# MSS_DMA_REG register map
Vendor: Texas Instruments
Peripheral module from a debugger description file (folder radar).
Registers are 32-bit, read-write, no defined reset value unless marked. A register's access mark holds for its fields unless they carry their own. Offsets are as the file gives them; lines under a group give offsets from that group; [hi:lo] are bit positions; {n}, {i} and the like mark numbered series; 'fields as' and 'values as' point back to an identical list; <NAME> marks a mode.

## MSS_DMA_REG
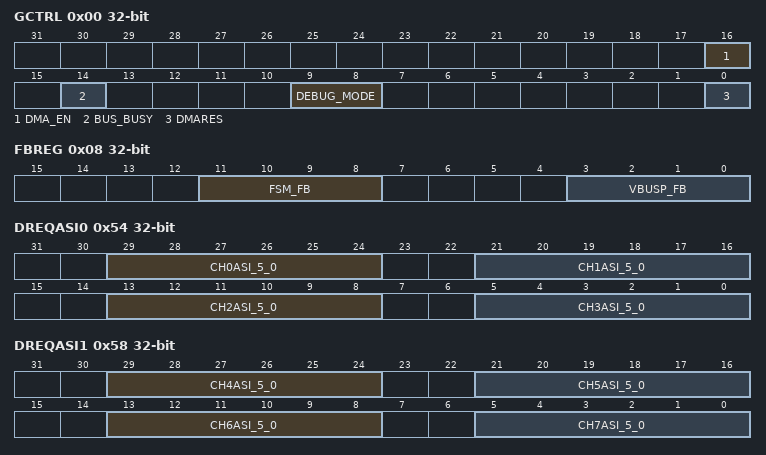
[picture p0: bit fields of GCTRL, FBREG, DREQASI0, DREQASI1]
0x00 GCTRL access per field — Sets Power-down mode, debug mode...
  [16] DMA_EN rw — DMA Enable bit
  [14] BUS_BUSY ro — BUS BUSY This bit indicates status of DMA external AHB bus status. 0 DMA’s external bus is not busy in data transfers. 1 DMA’s external bus is busy in data transfers
  [9:8] DEBUG_MODE rw — DEBUG MODE 11 immediate stop at an DMA arbitration boundary and continue after suspend 10 finish current frame transfer 01 finish current block transfer 00 ignore suspend
  [0] DMARES rw — DMA Software Reset Writing a 1 to this bit resets the DMA state machine and all control registers. Control packets are not reset when DMA software reset is active. Writing a zero disable SW reset.
0x04 PEND — Channel pending register
  [31:0] PEND — Channel Pending Register Writing has no effect. Reading from PEND gives the channel pending information no matter if the channel was initiated by SW or HW. Once set, it remains set even if the corresponding channel is disabled via HWCHENA or SWCHENA. The pending bit is automatically cleared for the following conditions: 1)At the end of a frame or a block transfer depending on how the channel is triggered as programmed in the TTYPE bit field of Section 1.6.3.4, "CHANNEL CONTROL Register (CHCTRL)" . 2)The control packet is modified after the pending bit is set. 3)An AHB bus error occurs. 1 the associated channel is pending and is waiting for service. 0 the associated channel is inactive.
0x08 FBREG access per field — Fall back register for EMC
  [11:8] FSM_FB rw — FSM_FB: FSM Fallback feature Used to switch off RTL clock gating for all FSM logics used for saving power. “1010” = Disable RTL clock gating in RTL. “0101” = Enable RTL clock gating in RTL. others = no effect will be in same state as before
  [3:0] VBUSP_FB rw — VBUSP_FB: VBUSP Fallback feature Used to switch off RTL clock gating for all VBUSP logics used for saving power. “1010” = Disable RTL clock gating in RTL. “0101” = Enable RTL clock gating in RTL. others = no effect will be in same state as before
0x0C DMASTAT — Channel active information
  [31:0] STCH — 0STCH: Status of DMA channels 1 channel active (means channel is currently in DMA’s execution queue). 0 channel inactive. Since the DMA has two Ports only two channels can be active at a time. Writing has no effect. Note: The status of a channel currently in DMA’s execution queue remains active even if emulation mode is entered or DMA is disabled via DMA_EN bit
{0x8+8i} MSS_DMA_Reserved{i} access not given (i=1..9)
0x14 HWCHENAS — Enables a channel for HW trigger
  [31:0] HWCHENA — HWCHENA: HW Channel Enable Bit Writing a one to a bit enables the according channel for HW triggering. Writing a zero has no effect. An active HW DMA request can not initiate DMA transfer unless the associated HW enable bit is set. The associated HW enable bit is cleared automatically for the following conditions: 1)At the end of a block transfer if autoinitiation bit AIM in Section 1.6.3.4, "CHANNEL CONTROL Register (CHCTRL)" is not active. 2)If an AHB bus error is detected for an active channel as indicated by HRESP signal. Reading from HWCHENAS gives the status (enabled/disabled) of channels 0 through 31. 1 the associated channel is enabled for HW triggering. 0 the associated channel is disabled for HW triggering.
0x1C HWCHENAR — Disables a channel for HW trigger
  [31:0] HWCHDIS — HW Channel Disable Bit. Writing a one to a bit disables the according channel for HW triggering. Writing a zero has no effect. Reading from CHENAR gives the status (enabled/disabled) of channels 0 through 31. 1 the associated channel is enabled for HW triggering. 0 the associated channel is disabled for HW triggering. Note: All Set and Reset registers throughout DMA controller such as HWCHENAS and HWCHENAR are two logical locations mapped to one physical register.
0x24 SWCHENAS — Activate a SW request
  [31:0] SWCHENA — SWCHENA: SW Channel Enable Bit. Writing a one to a bit trigger a SW request on the associated channel to start DMA transaction. The associated bit is automatically cleared by the following conditions. 1)The associated bit is cleared after one frame transfer if the TTYPE bit in Section 1.6.3.4, "CHANNEL CONTROL Register (CHCTRL)" is programmed for frame transfer. 2)The associated bit is cleared after one block transfer if the corresponding TTYPE bit is programmed for block transfer and the autoinitiation bit is not enabled. 3)The control packet is modified after the pending bit is set. 4)The associated bit is cleared after one block transfer when TTYPE bit is programmed for blocks transfer and if the corresponding bit in HW Channel Enable Register (HWCHENAS) is enabled. When a channel is enabled for both HW and SW, the state machine will initiate transfers based on the SW first. After one block transfer is complete, the associated bit in the SWCHENA register is then cleared. The same channel is serviced again by a HW DMA request. 5)The associated bit is cleared if an AHB bus error is detected for an active channel as indicated by HRESP signal. Reading from SWCHENAS gives the status (enabled/disabled) of channels 0 through 31 1 the associated channel was triggered by SW request. 0 the associated channel was not triggered by SW request
0x2C SWCHENAR — Disables a SW request
  [31:0] SWCHDIS — SWCHDIS: SW Channel Disable Bit Writing a one to a bit disables the according channel from SW trigger. Writing a zero has no effect. Reading from SWCHENAR gives the status (enabled/disabled) of channels 0 through 31. 1 the associated channel was triggered by SW. 0 the associated channel was not triggered by SW.
0x34 CHPRIOS — Enables a channel
  [31:0] CPH — CPH: Channel Priority Set Bit. Writing a one to a bit assigns the according channel to the high priority queue. Writing a zero has no effect. Reading from CHPRIOS gives the status (high priority 1 / low priority 0) of channels 0 through 31. 1 the associated channel is assigned to high priority queue. 0 the associated channel is assigned to low priority queue.
0x3C CHPRIOR — Disables a channel
  [31:0] CPL — CPL: Channel Priority Reset Bit Writing a one to a bit assigns the according channel to the low priority queue. Writing a zero has no effect. Reading from CHPRIOR gives the status (high priority 1 / low priority 0) of channels 0 through 31. 1 the associated channel is assigned to high priority queue. 0 the associated channel is assigned to low priority queue.
0x44 GCHIENAS — Enables the specific channel interrupts
  [31:0] GCHIE — GCHIE: Global Channel Interrupt Enable Bit. Writing a one to a bit enables the according channel interrupt. Writing a zero has no effect. Reading from GCHIENAS gives the status (enabled/disabled) of channels 0 through 31. 1 the associated channel is enabled for interrupt. 0 the associated channel is disabled for interrupt.
0x4C GCHIENAR — Disables the specific channel interrupts
  [31:0] GCHID — GCHID: Global Channel Interrupt Disable Bit Writing a one to a bit disables the according channel interrupt. Writing a zero has no effect. Reading from GCHIENAR gives the status (enabled/disabled) of channels 0 through 31. 1 the associated channel is enabled for interrupt. 0 the associated channel is disabled for interrupt
0x54 DREQASI0 access per field — DMA channel to request line assignment
  [29:24] CH0ASI_5_0 rw — CH0ASI: Channel 0 Assignment Bits This bit field chooses the DMA request assignment for channel 0. Writing 0 means DMA request line 0 coming in to the DMA will trigger channel 0. Writing 3F means DMA request line 63 will trigger channel 0.
  [21:16] CH1ASI_5_0 rw — CH1ASI: Channel 1 Assignment Bits This bit field chooses the DMA request assignment for channel 1.
  [13:8] CH2ASI_5_0 rw — CH2ASI: Channel 2 Assignment Bits This bit field chooses the DMA request assignment for channel 2.
  [5:0] CH3ASI_5_0 rw — CH3ASI: Channel 3 Assignment Bits. This bit field chooses the DMA request assignment for channel 3
0x58 DREQASI1 access per field — DMA channel to request line assignment
  [29:24] CH4ASI_5_0 rw — CH4ASI: Channel 4 Assignment Bits This bit field chooses the DMA request assignment for channel 4. .
  [21:16] CH5ASI_5_0 rw — CH5ASI: Channel 5 Assignment Bits This bit field chooses the DMA request assignment for channel 5
  [13:8] CH6ASI_5_0 rw — CH6ASI: Channel 6 Assignment Bits This bit field chooses the DMA request assignment for channel 6
  [5:0] CH7ASI_5_0 rw — CH7ASI: Channel 7 Assignment Bits. This bit field chooses the DMA request assignment for channel 7
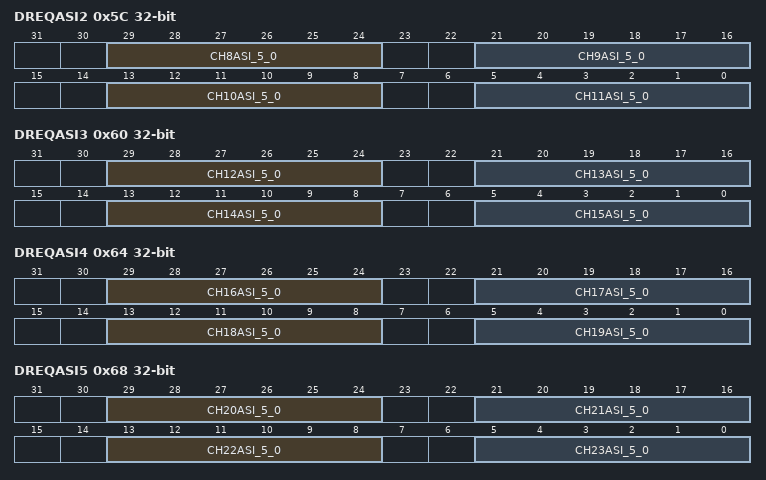
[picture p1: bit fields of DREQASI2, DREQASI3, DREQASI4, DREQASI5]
0x5C DREQASI2 access per field — DMA channel to request line assignment
  [29:24] CH8ASI_5_0 rw — CH8ASI: Channel 8 Assignment Bits This bit field chooses the DMA request assignment for channel 8
  [21:16] CH9ASI_5_0 rw — CH9ASI: Channel 9 Assignment Bits This bit field chooses the DMA request assignment for channel 9
  [13:8] CH10ASI_5_0 rw — CH10ASI: Channel 10 Assignment Bits This bit field chooses the DMA request assignment for channel 10
  [5:0] CH11ASI_5_0 rw — CH11ASI: Channel 11 Assignment Bits. This bit field chooses the DMA request assignment for channel 11
0x60 DREQASI3 access per field — DMA channel to request line assignment
  [29:24] CH12ASI_5_0 rw — CH12ASI: Channel 12 Assignment Bits This bit field chooses the DMA request assignment for channel 12
  [21:16] CH13ASI_5_0 rw — CH13ASI: Channel 13 Assignment Bits This bit field chooses the DMA request assignment for channel 13
  [13:8] CH14ASI_5_0 rw — CH14ASI: Channel 14 Assignment Bits This bit field chooses the DMA request assignment for channel 14
  [5:0] CH15ASI_5_0 rw — CH15ASI: Channel 15 Assignment Bits. This bit field chooses the DMA request assignment for channel 15
0x64 DREQASI4 access per field — DMA channel to request line assignment
  [29:24] CH16ASI_5_0 rw — CH16ASI: Channel 16 Assignment Bits This bit field chooses the DMA request assignment for channel 16
  [21:16] CH17ASI_5_0 rw — CH17ASI: Channel 17 Assignment Bits This bit field chooses the DMA request assignment for channel 17
  [13:8] CH18ASI_5_0 rw — CH18ASI: Channel 18 Assignment Bits This bit field chooses the DMA request assignment for channel 18
  [5:0] CH19ASI_5_0 rw — CH18ASI: Channel 19 Assignment Bits. This bit field chooses the DMA request assignment for channel 19
0x68 DREQASI5 access per field — DMA channel to request line assignment
  [29:24] CH20ASI_5_0 rw — CH20ASI: Channel 20 Assignment Bits This bit field chooses the DMA request assignment for channel 20
  [21:16] CH21ASI_5_0 rw — CH21ASI: Channel 21 Assignment Bits This bit field chooses the DMA request assignment for channel 21
  [13:8] CH22ASI_5_0 rw — CH22ASI: Channel 22 Assignment Bits This bit field chooses the DMA request assignment for channel 22
  [5:0] CH23ASI_5_0 rw — CH23ASI: Channel 23 Assignment Bits. This bit field chooses the DMA request assignment for channel 23
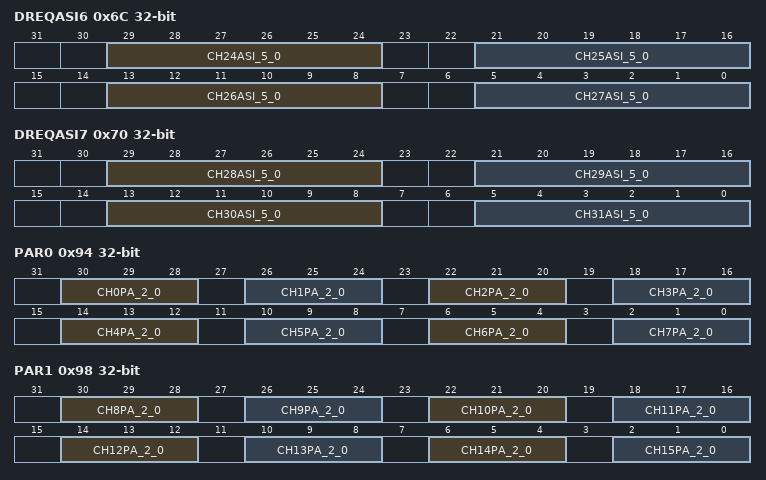
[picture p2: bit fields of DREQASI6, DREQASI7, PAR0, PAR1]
0x6C DREQASI6 access per field — DMA channel to request line assignment
  [29:24] CH24ASI_5_0 rw — CH24ASI: Channel 24 Assignment Bits This bit field chooses the DMA request assignment for channel 24
  [21:16] CH25ASI_5_0 rw — CH25SI: Channel 25 Assignment Bits This bit field chooses the DMA request assignment for channel 25
  [13:8] CH26ASI_5_0 rw — CH26ASI: Channel 26 Assignment Bits This bit field chooses the DMA request assignment for channel 26
  [5:0] CH27ASI_5_0 rw — CH27ASI: Channel 27 Assignment Bits. This bit field chooses the DMA request assignment for channel 27
0x70 DREQASI7 access per field — DMA channel to request line assignment
  [29:24] CH28ASI_5_0 rw — CH28ASI: Channel 28 Assignment Bits This bit field chooses the DMA request assignment for channel 28
  [21:16] CH29ASI_5_0 rw — CH29SI: Channel 29 Assignment Bits This bit field chooses the DMA request assignment for channel 29
  [13:8] CH30ASI_5_0 rw — CH30ASI: Channel 30 Assignment Bits This bit field chooses the DMA request assignment for channel 30
  [5:0] CH31ASI_5_0 rw — CH31ASI: Channel 31 Assignment Bits. This bit field chooses the DMA request assignment for channel 31
{0x4C+4i} MSS_DMA_Reserved{i} access not given (i=10..17)
0x94 PAR0 access per field — DMA channel to port assignment
  [30:28] CH0PA_2_0 rw — CH0PA These bit fields determine which port channel 0 is assigned. 1xx Port B 011 Port A2 only 010 Port A1 only 001 Port A1/2 combined, A2 read / A1 write 000 Port A1/2 combined, A1 read / A2 write
  [30-4n:28-4n] CH{n}PA_2_0 rw (n=1..7) — CH{n}PA These bit fields determine which port channel {n} is assigned
0x98 PAR1 access per field — DMA channel to port assignment
  [30:28] CH8PA_2_0 rw — CH8PA These bit fields determine which port channel 8 is assigned. 1xx Port B 011 Port A2 only 010 Port A1 only 001 Port A1/2 combined, A2 read / A1 write 000 Port A1/2 combined, A1 read / A2 write
  [62-4n:60-4n] CH{n}PA_2_0 rw (n=9..15) — CH{n}PA These bit fields determine which port channel {n} is assigned
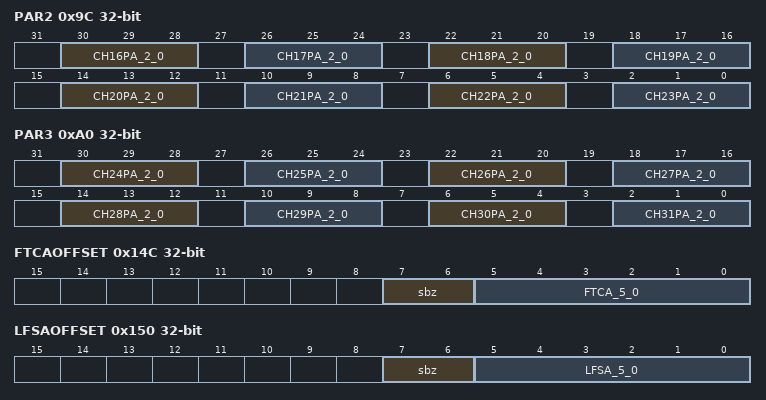
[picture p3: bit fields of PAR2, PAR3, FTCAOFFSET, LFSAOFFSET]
0x9C PAR2 access per field — DMA channel to port assignment
  [30:28] CH16PA_2_0 rw — CH16PA These bit fields determine which port channel 16 is assigned. 1xx Port B 011 Port A2 only 010 Port A1 only 001 Port A1/2 combined, A2 read / A1 write 000 Port A1/2 combined, A1 read / A2 write
  [94-4n:92-4n] CH{n}PA_2_0 rw (n=17..23) — CH{n}PA These bit fields determine which port channel {n} is assigned
0xA0 PAR3 access per field — DMA channel to port assignment
  [30:28] CH24PA_2_0 rw — CH24PA These bit fields determine which port channel 24 is assigned. 1xx Port B 011 Port A2 only 010 Port A1 only 001 Port A1/2 combined, A2 read / A1 write 000 Port A1/2 combined, A1 read / A2 write
  [126-4n:124-4n] CH{n}PA_2_0 rw (n=25..28) — CH{n}PA These bit fields determine which port channel {n} is assigned
  [10:8] CH29PA_2_0 rw — CH29PA These bit fields determine which port channel 28 is assigned
  [6:4] CH30PA_2_0 rw — CH30PA These bit fields determine which port channel 30 is assigned
  [2:0] CH31PA_2_0 rw — CH31PA These bit fields determine which port channel 31 is assigned
{0x5C+4i} MSS_DMA_Reserved{i} access not given (i=18..21)
0xB4 FTCMAP — Assignment of interrupt lines to either ARM CPU or DSP CPU
  [31:0] FTCAB — FTCAB: Frame Transfer Complete Interrupt to Group A or Group B 1 routes FTC interrupt of the corresponding channel to Group B. 0 routes FTC interrupt of the corresponding channel to Group A. Note: Group A interrupts (FTC, LFS, HBC, BTC and BER) are routed to ARM CPU. Group B interrupts (FTC, LFS, HBC, BTC and BER) are routed to DSP CPU.
{0x8+8i} MSS_DMA_Reserved{i} access not given (i=22..31)
0xBC LFSMAP — Assignment of interrupt lines to either ARM CPU or DSP CPU
  [31:0] LFSAB — LFSAB: Last Frame Started Interrupt to Group A or Group B 1 routes LFS interrupt of the corresponding channel to Group B. 0 routes LFS interrupt of the corresponding channel to Group A.
0xC4 HBCMAP — Assignment of interrupt lines to either ARM CPU or DSP CPU
  [31:0] HBCAB — HBCAB: Half Block Complete Interrupt to Group A or Group B 1 routes HBC interrupt of the corresponding channel to Group B. 0 routes HBC interrupt of the corresponding channel to Group A.
0xCC BTCMAP — Assignment of interrupt lines to either ARM CPU or DSP CPU
  [31:0] BTCAB — BTCAB: Block Transfer Complete Interrupt to Group A or Group B 1 routes BTC interrupt of the corresponding channel to Group B. 0 routes BTC interrupt of the corresponding channel to Group A.
0xD4 BERMAP — Assignment of interrupt lines to either ARM CPU or DSP CPU
  [31:0] BERAB — BERAB: Bus Error Interrupt to Group A or Group B. 1 routes BER interrupt of the corresponding channel to Group B. 0 routes BER interrupt of the corresponding channel to Group A.
0xDC FTCINTENAS — Enables a FTC interrupt for channels 0-31
  [31:0] FTCINTENA — FTCINTENA: FTC (Frame Transfer Complete) Interrupt Enable Bit. Writing a one to a bit enables the interrupt of the according channel. Writing a zero has no effect. Reading from FTCINTENAS gives the status (interrupt enabled/disabled) of channels 0 through 31. 1 the associated FTC interrupt of a channel is enabled. 0 the associated FTC interrupt of a channel is disabled.
0xE4 FTCINTENAR — Disables a FTC interrupt for channels 0-31
  [31:0] FTCINTDIS — FTCINTDIS: FTC (Frame Transfer Complete) Interrupt Disable Bit. Writing a one to a bit disables the interrupt of the according channel. Writing a zero has no effect. Reading from FTCINTENAR gives the status (interrupt enabled/disabled) of channels 0 through 31. 1 the associated FTC interrupt of a channel is enabled. 0 the associated FTC interrupt of a channel is disabled.
0xEC LFSINTENAS — Enables a LFS interrupt for channels 0-31
  [31:0] LFSINTENA — LFSINTENA: LFS (last Frame Started) Interrupt Enable Bit. Writing a one to a bit enables the interrupt of the according channel. Writing a zero has no effect Reading from LFSINTENAS gives the status (interrupt enabled/disabled) of channels 0 through 31. 1 the associated LFS interrupt of a channel is enabled. 0 the associated LFS interrupt of a channel is disabled
0xF4 LFSINTENAR — Disables a LFS interrupt for channels 0-31
  [31:0] LFSINTDIS — LFSINTDIS: LFS (Last Frame Started) Interrupt Disable Bit. Writing a one to a bit disables the interrupt of the according channel. Writing a zero has no effect. Reading from LFSINTENAR gives the status (interrupt enabled/disabled) of channels 0 through 31. 1 the associated LFS interrupt of a channel is enabled. 0 the associated LFS interrupt of a channel is disabled
0xFC HBCINTENAS — Enables a HBC interrupt for channels 0-31
  [31:0] HBCINTENA — HBCINTENA: HBC (Half Block Complete) Interrupt Enable Bit. Writing a one to a bit enables the interrupt of the according channel. Writing a zero has no effect. Reading from HBCINTENAS gives the status (interrupt enabled/disabled) of channels 0 through 31. 1 the associated HBC interrupt of a channel is enabled. 0 the associated HBC interrupt of a channel is disabled
0x104 HBCINTENAR — Disables a HBC interrupt for channels 0-31
  [31:0] HBCINTDIS — HBCINTDIS: HBC (Half Block Complete) Interrupt Disable Bit. Writing a one to a bit disables the interrupt of the according channel. Writing a zero has no effect Reading from HBCINTENAR gives the status (interrupt enabled/disabled) of channels 0 through 31. 1 the associated HBC interrupt of a channel is enabled. 0 the associated HBC interrupt of a channel is disabled
0x10C BTCINTENAS — Enables a BTC interrupt for channels 0-31
  [31:0] BTCINTENA — BTCINTENA: BTC (Block Transfer Complete) Interrupt Enable Bit. Writing a one to a bit enables the interrupt of the according channel. Writing a zero has no effect. Reading from BTCINTENAS gives the status (interrupt enabled/disabled) of channels 0 through 31. 1 the associated BTC interrupt of a channel is enabled. 0 the associated BTC interrupt of a channel is disabled.
{0x8+8i} MSS_DMA_Reserved{i} access not given (i=33..40)
0x114 BTCINTENAR — Disables a BTC interrupt for channels 0-31
  [31:0] BTCINTDIS — BTCINTDIS: BTC (Block Transfer Complete) Interrupt Disable Bit. Writing a one to a bit disables the interrupt of the according channel. Writing a zero has no effect. Reading from BTCINTENAR gives the status (interrupt enabled/disabled) of channels 0 through 31. 1 the associated BTC interrupt of a channel is enabled. 0 the associated BTC interrupt of a channel is disabled
0x11C GINTFLAG — Each flag bit is an OR of five different interrupt types of the same channel
  [31:0] GINT — GINT: Global Interrupt Flags. Global interrupt flag bit is a OR function of FTC, LFS, HBC, BTC and BER interrupt flags. When a bit is active, it indicates that one or more of the five interrupt types is pending of the corresponding channel
0x124 FTCFLAG — FTC Interrupt flags Channels 0-31
  [31:0] FTC — FTCI: Frame Transfer Complete Flags. If the bit is set a FTC Interrupt of the corresponding channels pending. Writing a 1 clears the according flag. Writing a zero has no effect. Reading from the respected Interrupt Channel Offset register also clears the corresponding flag. 1 the associated FTC interrupt of a channel is pending. 0 the associated FTC interrupt of a channel is not pending. The state of the flag bit can be polled even if the corresponding interrupt enable bit is cleared
0x12C LFSFLAG — LFS Interrupt flags Channels 0-31
  [31:0] LFSI — LFSI: Last Frame Transfer Started Flags If the bit is set a LFS Interrupt of the corresponding channels pending. Writing a 1 clears the according flag. Writing a zero has no effect. Reading from the respected Interrupt Channel Offset register also clears the corresponding flag. 1 the associated LFS interrupt of a channel is pending. 0 the associated LFS interrupt of a channel is not pending. The state of the flag bit can be polled even if the corresponding interrupt enable bit is cleared
0x134 HBCFLAG — HBC Interrupt flags Channels 0-31
  [31:0] HBCI — HBCI: Half of Block Transfer Complete Flags. If the bit is set a HBC Interrupt of the corresponding channels pending. Writing a 1 clears the according flag. Writing a zero has no effect. Reading from the respected Interrupt Channel Offset register also clears the corresponding flag. 1 the associated HBC interrupt of a channel is pending. 0 the associated HBC interrupt of a channel is not pending. The state of the flag bit can be polled even if the corresponding interrupt enable bit is cleared
0x13C BTCFLAG — BTC Interrupt flags Channels 0-31
  [31:0] BTCI — BTCI: Block Transfer Complete Flags. If the bit is set a BTC Interrupt of the corresponding channels pending. Writing a 1 clears the according flag. Writing a zero has no effect. Reading from the respected Interrupt Channel Offset register also clears the corresponding flag. 1 the associated BTC interrupt of a channel is pending. 0 the associated BTC interrupt of a channel is not pending. The state of the flag bit can be polled even if the corresponding interrupt enable bit is cleared
0x144 BERFLAG — BER Interrupt flags Channels 0-31
  [31:0] BERI — BERI: Bus Error Flags. If the bit is set a BER Interrupt of the corresponding channels pending. Writing a 1 clears the according flag. Writing a zero has no effect. Reading from the respected Interrupt Channel Offset register also clears the corresponding flag. 1 the associated BER interrupt of a channel is pending. 0 the associated BER interrupt of a channel is not pending. The state of the flag bit can be polled even if the corresponding interrupt enable bit is cleared.
0x14C FTCAOFFSET ro — Channel causing FTC Interrupt on Group A
  [7:6] sbz — sbz. These bits should be programmed as zero
  [5:0] FTCA_5_0 — FTCA: Channel causing FTC (Frame Transfer Complete) Interrupt Group A. Contains the channel number of the pending interrupt for group A if the corresponding interrupt enable is set. Reading this location clears the corresponding Interrupt pending flag with the highest priority. Please refer to Table 1–10. If FTCA is zero it means no interrupt is pending. FTCA = 1, means channel 0 is pending. FTCA = 2, means channel 1 is pending and so on... FTCA Interrupt Offset Index Interrupt Condition Offset Value Phantom 0x0 Channel 0 FTCA 0x1 Channel 1 FTCA 0x2 | | | | Channel 31 FTCA 0x20
0x150 LFSAOFFSET ro — Channel causing LFS Interrupt on Group A
  [7:6] sbz — 6sbz. These bits should be programmed as zero.
  [5:0] LFSA_5_0 — LFSA: Channel causing LFS (Last Frame Started) Interrupt Group A. Contains the channel number of the pending interrupt for group A if the corresponding interrupt enable is set. Reading this location clears the corresponding Interrupt pending flag with the highest priority. Please refer below table FTCA Interrupt Offset Index Interrupt Condition Offset Value Phantom 0x0 Channel 0 FTCA 0x1 Channel 1 FTCA 0x2 | | | | Channel 31 FTCA 0x20
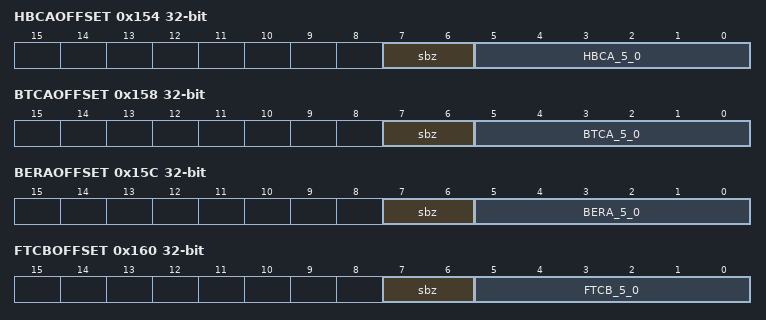
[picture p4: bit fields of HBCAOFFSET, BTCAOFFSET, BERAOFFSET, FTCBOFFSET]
0x154 HBCAOFFSET ro — Channel causing HBC Interrupt on Group A
  [7:6] sbz — sbz. These bits should be programmed as zero
  [5:0] HBCA_5_0 — HBCA: Channel causing HBC (Half Block Complete) Interrupt Group A. Contains the channel number of the pending interrupt for group A if the corresponding interrupt enable is set. Reading this location clears the corresponding Interrupt pending flag with the highest priority. Please refer to below table FTCA Interrupt Offset Index Interrupt Condition Offset Value Phantom 0x0 Channel 0 FTCA 0x1 Channel 1 FTCA 0x2 | | | | Channel 31 FTCA 0x20
0x158 BTCAOFFSET ro — Channel causing BTC Interrupt on Group A
  [7:6] sbz — sbz. These bits should be programmed as zero
  [5:0] BTCA_5_0 — BTCA: Channel causing BTC (Block Transfer Complete) Interrupt Group A. Contains the channel number of the pending interrupt for group A if the corresponding interrupt enable is set. Reading this location clears the corresponding Interrupt pending flag with the highest priority.
0x15C BERAOFFSET ro — Channel causing BER Interrupt on Group A
  [7:6] sbz — sbz. These bits should be programmed as zero
  [5:0] BERA_5_0 — BERA: Channel causing BER (Bus Error) Interrupt Group A. Contains the channel number of the pending interrupt for group A if the corresponding interrupt enable is set. Reading this location clears the corresponding Interrupt pending flag with the highest priority
0x160 FTCBOFFSET ro — Channel causing FTC Interrupt on Group B
  [7:6] sbz — sbz. These bits should be programmed as zero
  [5:0] FTCB_5_0 — FTCB: Channel causing FTC (Frame Transfer Complete) Interrupt Group B. Contains the channel number of the pending interrupt for group B. Reading this location clears the corresponding Interrupt pending flag with the highest priority. Please refer to below table FTCA Interrupt Offset Index Interrupt Condition Offset Value Phantom 0x0 Channel 0 FTCA 0x1 Channel 1 FTCA 0x2 | | | | Channel 31 FTCA 0x20
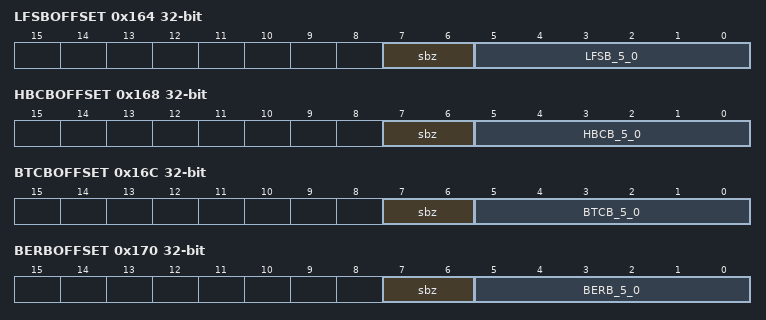
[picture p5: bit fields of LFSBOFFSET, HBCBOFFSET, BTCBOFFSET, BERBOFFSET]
0x164 LFSBOFFSET ro — Channel causing LFS Interrupt on Group B
  [7:6] sbz — sbz. These bits should be programmed as zero
  [5:0] LFSB_5_0 — LFSB: Channel causing LFS (Last Frame Started) Interrupt Group B. Contains the channel number of the pending interrupt for group B if the corresponding interrupt enable is set. Reading this location clears the corresponding Interrupt pending flag with the highest priority. Please refer to below table FTCA Interrupt Offset Index Interrupt Condition Offset Value Phantom 0x0 Channel 0 FTCA 0x1 Channel 1 FTCA 0x2 | | | | Channel 31 FTCA 0x20
0x168 HBCBOFFSET ro — Channel causing HBC Interrupt on Group B
  [7:6] sbz — sbz. These bits should be programmed as zero
  [5:0] HBCB_5_0 — 0HBCB: Channel causing HBC (Half Block Complete) Interrupt Group B. Contains the channel number of the pending interrupt for group B if the corresponding interrupt enable is set. Reading this location clears the corresponding Interrupt pending flag with the highest priority. Please refer to below table FTCA Interrupt Offset Index Interrupt Condition Offset Value Phantom 0x0 Channel 0 FTCA 0x1 Channel 1 FTCA 0x2 | | | | Channel 31 FTCA 0x20
0x16C BTCBOFFSET ro — Channel causing BTC Interrupt on Group B
  [7:6] sbz — sbz. These bits should be programmed as zero
  [5:0] BTCB_5_0 — BTCB: Channel causing BTC (Block Transfer Complete) Interrupt Group B. Contains the channel number of the pending interrupt for group B if the corresponding interrupt enable is set. Reading this location clears the corresponding Interrupt pending flag with the highest priority. Please refer to below table FTCA Interrupt Offset Index Interrupt Condition Offset Value Phantom 0x0 Channel 0 FTCA 0x1 Channel 1 FTCA 0x2 | | | | Channel 31 FTCA 0x20
0x170 BERBOFFSET ro — Channel causing BER Interrupt on Group B
  [7:6] sbz — sbz. These bits should be programmed as zero
  [5:0] BERB_5_0 — BERB: Channel causing BER (Bus Error) Interrupt Group B. Contains the channel number of the pending interrupt for group B if the corresponding interrupt enable is set. Reading this location clears the corresponding Interrupt pending flag with the highest priority. Please refer to below table FTCA Interrupt Offset Index Interrupt Condition Offset Value Phantom 0x0 Channel 0 FTCA 0x1 Channel 1 FTCA 0x2 | | | | Channel 31 FTCA 0x20
0x174 MSS_DMA_Reserved41 access not given
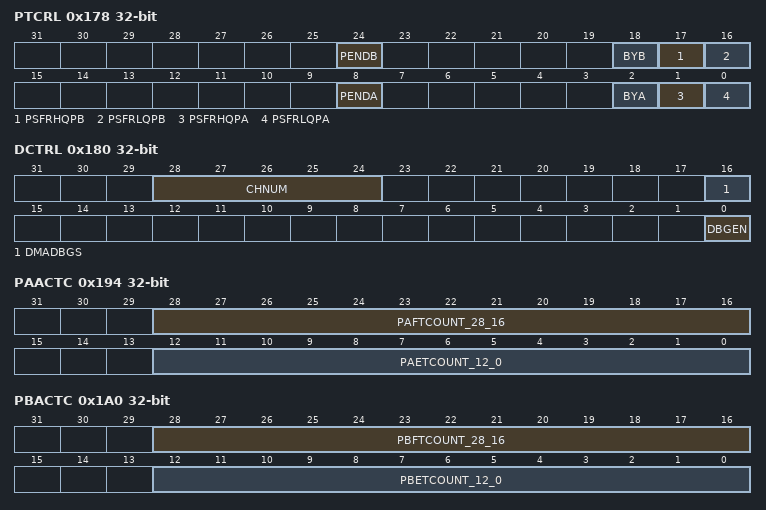
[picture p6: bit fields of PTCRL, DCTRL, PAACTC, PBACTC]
0x178 PTCRL access per field — Port Control and Status...
  [24] PENDB ro — PENDB: Transactions Pending for Port B. This flag determines if there are transactions ongoing on Port B. The flag will be cleared if no transfers are done. It can be used to determine if there is still data transfered while DMA_EN is set to 0 in GCTCRL. In this case, once all transfers are finished, the flag will be set to 0. 1 Transfers are still pending 0 No transfers are pending
  [18] BYB rw — BYB: Bypass FIFO B. Writing 1 to this bit limits the FIFO depth to the size of one element. That means after one element is read the write out to the destination will start. This feature is particularly useful to minimize switching latency in-between channels. But it also does not make optimal use of AHB bandwidth.
  [17] PSFRHQPB rw — PSFRHQPB: Priority Scheme Fix or Rotate for High Priority Queue of Port B. 1 Rotation priority 0 Fixed priority
  [16] PSFRLQPB rw — PSFRLQPB: Priority Scheme Fix or Rotate for Low Priority Queue of Port B. 1 Rotation priority 0 Fixed priority
  [8] PENDA ro — PENDA: Transactions Pending for Port A. This flag determines if there are transactions ongoing on Port A. The flag will be cleared if no transfers are done. It can be used to determine if there is still data transfered while DMA_EN is set to 0 in GCTCRL. In this case, once all transfers are finished, the flag will be set to 0. 1 Transfers are still pending 0 No transfers are pending
  [2] BYA rw — BYA: Bypass FIFO A. Writing 1 to this bit limits the FIFO depth to the size of one element. That means after one element is read the write out to the destination will start. This feature is particularly useful to minimize switching latency in-between channels. But it also does not make optimal use of AHB bandwidth
  [1] PSFRHQPA rw — PSFRHQPA: Priority Scheme Fix or Rotate for High Priority Queue of Port A. 1 Rotation priority 0 Fixed priority
  [0] PSFRLQPA rw — PSFRLQPA: Priority Scheme Fix or Rotate for Low Priority Queue of Port A. 1 Rotation priority 0 Fixed priority
0x17C RTCTRL access per field — test bit to open write access to CPU during test mode
  [0] RTC rw — RTC: RAM Test Control Writing a one to this bit open the write access to the reserved locations of control packet RAM as defined in the memory map. Writing a zero will prohibit write access to the reserved locations of control packet RAM
0x180 DCTRL access per field — Control bit to enable watchpoint checking
  [28:24] CHNUM rw — CHNUM : Channel Number. These bit fields indicate the channel number which causes the watchpoint to match
  [16] DMADBGS rw — DMADBGS: DMA Debug Status. When a watchpoint is setup to watch for an unique AHB address or a range of addresses is true on one of the three AHB ports is true then DMA Debug Status bit is set and a debug request signal is asserted to the main CPU. CPU must write one to clear this bit in order for DMA to release debug request signal. When this bit is read: 0 = No watchpoint condition is detected. 1 = Watchpoint condition is detected. When this is written: 0 = No effect. 1 = Clears the bit
  [0] DBGEN rw — DBGEN: Debug Enable Writing a one to this bit enable the watchpoint checking logics. This bit can only be set during emulation mode when SUSPEND is high. Also this bit is reset by test reset (nTRST).
0x184 WPR — watch for an address on AHB bus of either PortA1, PortA2 and PortB
  [31:0] WP — WP: Watch Point Register. This register can only be programmed during emulation mode when SUSPEND signal is high. Also this register is only reset by a test reset (nTRST). A 32 bit address can be programmed into this register as a watchpoint. This register is used along with Watch Mask Register (WMR) as described in the next section. When DBGEN bit is set and a unique address or a range of addresses are detected on the AHB address bus of either Port A1, Port A2 or Port B, a debug request signal is sent to ARM CPU. The state machine of the port in which the watchpoint condition is true is frozen
0x188 WMR — mask out a bit in watch point register from address compare
  [31:0] WM — WM: Watch Mask Register. This register can only be programmed during emulation mode when SUSPEND signal is high. Also this register is only reset by a test reset (nTRST). Setting a bit to 1 in the WMR register has the effect of masking the corresponding bit in the WPR register disregarded in the comparison.
0x18C PAACSADDR — The current source address of an ongoing active channel in Port A
  [31:0] PAACSA — PAACSA: PortA Active Channel Source Address. This register contains the current source address of the active channel as broadcasted in Section 1.6.2.4, "DMA STATUS Register (DMASTAT)" for Port A
0x190 PAACDADDR — The destination address of an ongoing active channel in Port A
  [31:0] PAACDA — PAACDA: PortA Active Channel Destination Address. This register contains the current destination address of the active channel as broadcasted in Section 1.6.2.4, "DMA STATUS Register (DMASTAT)" for Port A.
0x194 PAACTC ro — The transfer count of an ongoing active channel in Port B
  [28:16] PAFTCOUNT_28_16 — PAFTCOUNT: PortA Active Channel Frame Count. This register contains the current frame count value of the active channel as broadcasted in Section 1.6.2.4, "DMA STATUS Register (DMASTAT)" for Port A
  [12:0] PAETCOUNT_12_0 — PAETCOUNT: PortA Active Channel Element Count. This register contains the current element count value of the active channel as broadcasted in Section 1.6.2.4, "DMA STATUS Register (DMASTAT)" for Port A. Note: PAETCOUNT and PAFTCOUNT indicate the count values of the active channel currently residing in DMA’s execution queue. With multiple pending channels and due to arbitration between channels the PAETCOUNT and PAFTCOUNT should not be polled to determine the end of a channel transfer.
0x198 PBACSADDR — The current source address of an ongoing active channel in Port B
  [31:0] PBACSA — PBACSA: PortB Active Channel Source Address. This register contains the current source address of the active channel as broadcasted in Section 1.6.2.4, "DMA STATUS Register (DMASTAT)" for Port B.
0x19C PBACDADDR — The destination address of an ongoing active channel in Port B
  [31:0] PBACDA — PBACDA: PortB Active Channel Destination Address. This register contains the current destination address of the active channel as broadcasted in Section 1.6.2.4, "DMA STATUS Register (DMASTAT)" for Port B.
0x1A0 PBACTC access per field — The transfer count of an ongoing active channel in Port B
  [28:16] PBFTCOUNT_28_16 rw — PBFTCOUNT: PortB Active Channel Frame Count. This register contains the current frame count value of the active channel as broadcasted in Section 1.6.2.4, "DMA STATUS Register (DMASTAT)" for Port B.
  [12:0] PBETCOUNT_12_0 rw — PBETCOUNT: PortB Active Channel Element Count. This register contains the current element count value of the active channel as broadcasted in Section 1.6.2.4, "DMA STATUS Register (DMASTAT)" for Port B.
0x1A4 MSS_DMA_Reserved42 access not given
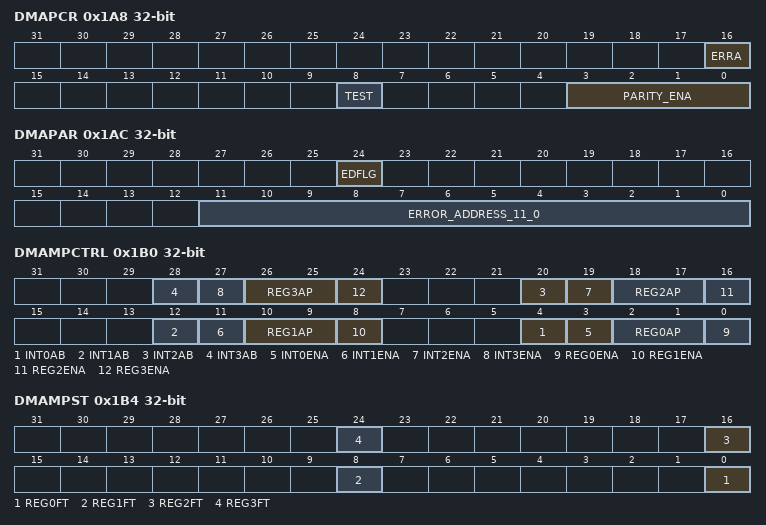
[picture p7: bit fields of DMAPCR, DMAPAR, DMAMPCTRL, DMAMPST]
0x1A8 DMAPCR access per field — Control of the parity generation
  [16] ERRA rw — ERRA: Error Action 0 = If a parity error is detected on Control Packet x (x = 0, 1, ...or 31), then the enable/disable state of Control Packet x remains unchanged. 1 = If a parity error is detected on Control Packet x (x = 0, 1, ...or 31), then DMA is disabled immediately. If a frame on Control Packet x is processed at the time the parity error is detected, then remaining elements of this frame will no more be transferred. Disabling of the DMA will be done, regardless of whether the error was detected during a read to the Control Packet RAM performed by the DMA state machine or by a different master.
  [8] TEST rw — TEST. When this bit is set, the parity bits are memory mapped to make them accessible by the CPU. 0 = parity bits are not memory mapped 1 = parity bits are memory mapped
  [3:0] PARITY_ENA rw — PARITY_ENA: Parity Error Detection Enable. This bit field enables or disables the parity check on read operations and the parity calculation on write operations. If parity checking is enabled and a parity error is detected the DMA_UERR signal is activated. During memory initiallization this bit field needs to be enable inorder to generate parity bits inside memory. 0101 = disable all other = enable NOTE: It is recommended to write a ‘1010’ to enable error detection, to guard against soft error from flipping PARITY_ENA to a disable state
0x1AC DMAPAR ro — The address of the control packet memory, where the uncorrectable error occured
  [24] EDFLG — EDFLG: Parity Error Detection Flag. This flag indicates if a parity error occured on reading DMA Control packet RAM. When this bit is read: 0 = No error occured. 1 = Error detected and the address is captured in DMAPAR’s ERROR_ADDRESS field. When write to this bit with: 0 = No effect. 1 = Clears the bit.
  [11:0] ERROR_ADDRESS_11_0 — ERROR ADDRESS: Error Address. This register holds the address of the first parity error generated in the RAM. This error address is frozen from being updated until it is read by the CPU. During emulation mode when SUSPEND is high, this address is frozen even when read. NOTE: The Error Address Register (11:0) will not be reset, neither by PORRST nor by any other reset source.
0x1B0 DMAMPCTRL access per field — Controls enablin/disabling of the protection regions and access restrictions
  [8n+4] INT{n}AB rw (n=0..3) — INT{n}AB: Interrupt assignment of region {n} to Group A or GroupB. 0 = Interrupt is routed to VIM (Group A) 1 = Interrupt is routed to DSP CPU (Group B)
  [8n+3] INT{n}ENA rw (n=0..3) — INT{n}ENA: Interrupt enable of region {n}. 0 = Interrupt is disabled 1 = Interrupt is enabled
  [26:25] REG3AP rw — REG3AP: Region 3 Access Permission. These bits determine the access permission for region 3 REG3AP Access Permission 00 all accesses allowed 01 read only 10 write only 11 none
  [8n] REG{n}ENA rw (n=0..3) — REG{n}ENA: Region {n} Enable. 0 = Region is disabled (no address checking done) 1 = Region is enalbed (address and access permission checking done)
  [18:17] REG2AP rw — REG2AP: Region 2 Access Permission. These bits determine the access permission for region 2 REG2AP Access Permission 00 all accesses allowed 01 read only 10 write only 11 none
  [10:9] REG1AP rw — REG1AP: Region 1 Access Permission These bits determine the access permission for region 1 REG1AP Access Permission 00 all accesses allowed 01 read only 10 write only 11 none
  [2:1] REG0AP rw — REG0AP: Region 0 Access Permission. These bits determine the access permission for region 0 REG0AP Access Permission 00 all accesses allowed 01 read only 10 write only 11 none
0x1B4 DMAMPST ro — Status bits to show in which region a access violation happened
  [8n] REG{n}FT (n=0..3) — REG{n}FT: Region {n} Fault. This bit determines whether a access permission violation was detected in this region. Once the bit is set, it can be cleared by writing a 1. 0 = no fault detected 1 = fault detected
0x1B8 DMAMPR0S — Defines starting address of region 0
  [31:0] STARTADDRESS — STARTADDRESS - Region 0 The startaddress defines at which address the region begins
{0x1BC+8i} DMAMPR{i}E (i=0..3) — Defines end address of region {i}
  [31:0] ENDADDRESS — ENDADDRESS - Region {i} The endaddress defines at which address the region ends. The endaddress usually is bigger than the startaddress for this region. Otherwise the region will wrap around at the end of the address space.
0x1C0 DMAMPR1S — Defines starting address of region 1
  [31:0] STARTADDRESS — STARTADDRESS - Region 1 The startaddress defines at which address the region begins
0x1C8 DMAMPR2S — Defines starting address of region 2
  [31:0] STARTADDRESS — STARTADDRESS - Region 2 The startaddress defines at which address the region begins.
0x1D0 DMAMPR3S — Defines starting address of region 3
  [31:0] STARTADDRESS — STARTADDRESS - Region 3 The startaddress defines at which address the region begins.
